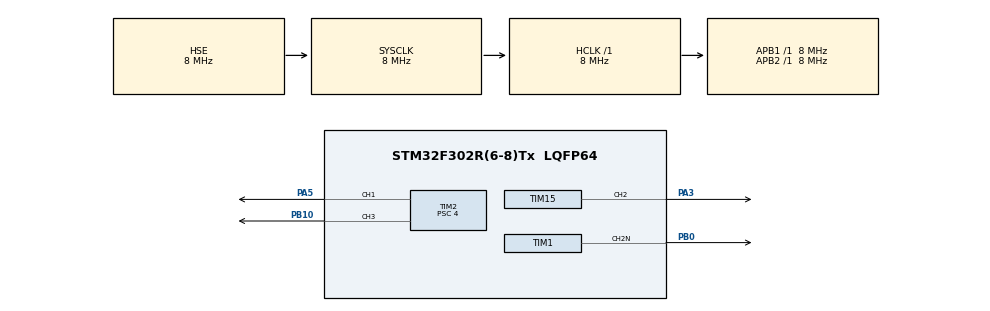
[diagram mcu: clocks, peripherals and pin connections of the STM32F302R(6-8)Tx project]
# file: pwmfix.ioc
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Mcu.Family=STM32F3
Mcu.Name=STM32F302R(6-8)Tx
Mcu.Package=LQFP64
NVIC.PriorityGroup=NVIC_PRIORITYGROUP_4
PA3.Signal=S_TIM15_CH2
PA5.Signal=S_TIM2_CH1_ETR
PB0.Mode=PWM Generation2 CH2N
PB0.Signal=TIM1_CH2N
PB10.Signal=S_TIM2_CH3
PF0-OSC_IN.Mode=HSE-External-Oscillator
PF0-OSC_IN.Signal=RCC_OSC_IN
PF1-OSC_OUT.Mode=HSE-External-Oscillator
PF1-OSC_OUT.Signal=RCC_OSC_OUT
ProjectManager.HeapSize=0x200
ProjectManager.StackSize=0x400
ProjectManager.TargetToolchain=MDK-ARM V5
RCC.AHBFreq_Value=8000000
RCC.APB1Freq_Value=8000000
RCC.APB1TimFreq_Value=8000000
RCC.APB2Freq_Value=8000000
RCC.APB2TimFreq_Value=8000000
RCC.CortexFreq_Value=8000000
RCC.HCLKFreq_Value=8000000
RCC.HSE_VALUE=8000000
RCC.HSI_VALUE=8000000
RCC.LSE_VALUE=32768
RCC.PLLSourceVirtual=RCC_PLLSOURCE_HSE
RCC.SYSCLKFreq_VALUE=8000000
RCC.SYSCLKSourceVirtual=RCC_SYSCLKSOURCE_HSE
RCC.USBFreq_Value=16000000
SH.S_TIM15_CH2.0=TIM15_CH2,PWM Generation2 CH2
SH.S_TIM2_CH1_ETR.0=TIM2_CH1,PWM Generation1 CH1
SH.S_TIM2_CH3.0=TIM2_CH3,PWM Generation3 CH3
TIM1.AutoReloadPreload=TIM_AUTORELOAD_PRELOAD_DISABLE
TIM1.Channel-PWM\ Generation2\ CH2N=TIM_CHANNEL_2
TIM1.OCNPolarity_2=TIM_OCNPOLARITY_HIGH
TIM1.Period=79
TIM1.Prescaler=4
TIM1.Pulse-PWM\ Generation2\ CH2N=39
TIM1.TIM_MasterSlaveMode=TIM_MASTERSLAVEMODE_DISABLE
TIM15.Channel-PWM\ Generation2\ CH2=TIM_CHANNEL_2
TIM15.OCPolarity_2=TIM_OCPOLARITY_LOW
TIM15.Period=79
TIM15.Prescaler=4
TIM15.Pulse-PWM\ Generation2\ CH2=39
TIM15.TIM_MasterOutputTrigger=TIM_TRGO_ENABLE
TIM15.TIM_MasterSlaveMode=TIM_MASTERSLAVEMODE_ENABLE
TIM2.AutoReloadPreload=TIM_AUTORELOAD_PRELOAD_ENABLE
TIM2.Channel-PWM\ Generation1\ CH1=TIM_CHANNEL_1
TIM2.Channel-PWM\ Generation3\ CH3=TIM_CHANNEL_3
TIM2.OCPolarity_3=TIM_OCPOLARITY_LOW
TIM2.Period=79
TIM2.Prescaler=4
TIM2.Pulse-PWM\ Generation1\ CH1=39
TIM2.Pulse-PWM\ Generation3\ CH3=39
TIM2.TIM_MasterOutputTrigger=TIM_TRGO_ENABLE
TIM2.TIM_MasterSlaveMode=TIM_MASTERSLAVEMODE_ENABLE
VP_TIM15_VS_ClockSourceINT.Mode=Internal
VP_TIM15_VS_ClockSourceITR.Mode=TriggerSource_ITR0
VP_TIM15_VS_ControllerModeTrigger.Mode=Trigger Mode
VP_TIM1_VS_ClockSourceINT.Mode=Internal
VP_TIM1_VS_ClockSourceITR.Mode=TriggerSource_ITR0
VP_TIM1_VS_ControllerModeCombinedResetTrigger.Mode=Combined_Reset_Trigger_Mode
VP_TIM2_VS_ClockSourceINT.Mode=Internal
board=custom

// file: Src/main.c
/**
  ******************************************************************************
  * @file           : main.c
  * @brief          : Main program body
  ******************************************************************************
  ** This notice applies to any and all portions of this file
  * that are not between comment pairs USER CODE BEGIN and
  * USER CODE END. Other portions of this file, whether
  * inserted by the user or by software development tools
  * are owned by their respective copyright owners.
  *
  * COPYRIGHT(c) 2019 STMicroelectronics
  *
  * Redistribution and use in source and binary forms, with or without modification,
  * are permitted provided that the following conditions are met:
  *   1. Redistributions of source code must retain the above copyright notice,
  *      this list of conditions and the following disclaimer.
  *   2. Redistributions in binary form must reproduce the above copyright notice,
  *      this list of conditions and the following disclaimer in the documentation
  *      and/or other materials provided with the distribution.
  *   3. Neither the name of STMicroelectronics nor the names of its contributors
  *      may be used to endorse or promote products derived from this software
  *      without specific prior written permission.
  *
  * THIS SOFTWARE IS PROVIDED BY THE COPYRIGHT HOLDERS AND CONTRIBUTORS "AS IS"
  * AND ANY EXPRESS OR IMPLIED WARRANTIES, INCLUDING, BUT NOT LIMITED TO, THE
  * IMPLIED WARRANTIES OF MERCHANTABILITY AND FITNESS FOR A PARTICULAR PURPOSE ARE
  * DISCLAIMED. IN NO EVENT SHALL THE COPYRIGHT HOLDER OR CONTRIBUTORS BE LIABLE
  * FOR ANY DIRECT, INDIRECT, INCIDENTAL, SPECIAL, EXEMPLARY, OR CONSEQUENTIAL
  * DAMAGES (INCLUDING, BUT NOT LIMITED TO, PROCUREMENT OF SUBSTITUTE GOODS OR
  * SERVICES; LOSS OF USE, DATA, OR PROFITS; OR BUSINESS INTERRUPTION) HOWEVER
  * CAUSED AND ON ANY THEORY OF LIABILITY, WHETHER IN CONTRACT, STRICT LIABILITY,
  * OR TORT (INCLUDING NEGLIGENCE OR OTHERWISE) ARISING IN ANY WAY OUT OF THE USE
  * OF THIS SOFTWARE, EVEN IF ADVISED OF THE POSSIBILITY OF SUCH DAMAGE.
  *
  ******************************************************************************
  */
#include "main.h"
#include "stm32f3xx_hal.h"

/* USER CODE BEGIN Includes */
#include "stdlib.h"
/* USER CODE END Includes */

TIM_HandleTypeDef htim1;
TIM_HandleTypeDef htim2;
TIM_HandleTypeDef htim15;

/* USER CODE BEGIN PV */
/* Private variables ---------------------------------------------------------*/
//TIM_HandleTypeDef htim1;
//TIM_HandleTypeDef htim2;
/* USER CODE END PV */

void SystemClock_Config(void);
static void MX_GPIO_Init(void);
static void MX_TIM1_Init(void);
static void MX_TIM2_Init(void);
static void MX_TIM15_Init(void);
void HAL_TIM_MspPostInit(TIM_HandleTypeDef *htim);

/* USER CODE BEGIN PFP */
/* Private function prototypes -----------------------------------------------*/
void updateDutyCycleBoost(int duty);
/* USER CODE END PFP */

int main(void)
{

  /* MCU Configuration----------------------------------------------------------*/

  /* Reset of all peripherals, Initializes the Flash interface and the Systick. */
  HAL_Init();

  /* Configure the system clock */
  SystemClock_Config();

  /* Initialize all configured peripherals */
  MX_GPIO_Init();
  MX_TIM1_Init();
  MX_TIM2_Init();
  MX_TIM15_Init();
  /* USER CODE BEGIN 2 */
	//HAL_TIM_PWM_Start(&htim1, TIM_CHANNEL_1);

	HAL_TIMEx_PWMN_Start(&htim1, TIM_CHANNEL_2);
	HAL_TIM_PWM_Start(&htim2, TIM_CHANNEL_1);
	HAL_TIM_PWM_Start(&htim2, TIM_CHANNEL_3);
	//HAL_TIM_PWM_Start(&htim2, TIM_CHANNEL_4);
	HAL_TIM_PWM_Start(&htim15, TIM_CHANNEL_2);

	__HAL_TIM_ENABLE(&htim2);

	updateDutyCycleBoost(50);

  /* USER CODE END 2 */

  /* Infinite loop */
  while (1)
  {

  }

}

void SystemClock_Config(void)
{

  RCC_OscInitTypeDef RCC_OscInitStruct;
  RCC_ClkInitTypeDef RCC_ClkInitStruct;
  RCC_PeriphCLKInitTypeDef PeriphClkInit;

    /**Initializes the CPU, AHB and APB busses clocks
    */
  RCC_OscInitStruct.OscillatorType = RCC_OSCILLATORTYPE_HSE;
  RCC_OscInitStruct.HSEState = RCC_HSE_ON;
  RCC_OscInitStruct.HSIState = RCC_HSI_ON;
  RCC_OscInitStruct.PLL.PLLState = RCC_PLL_NONE;
  if (HAL_RCC_OscConfig(&RCC_OscInitStruct) != HAL_OK)
  {
    _Error_Handler(__FILE__, __LINE__);
  }

    /**Initializes the CPU, AHB and APB busses clocks
    */
  RCC_ClkInitStruct.ClockType = RCC_CLOCKTYPE_HCLK|RCC_CLOCKTYPE_SYSCLK
                              |RCC_CLOCKTYPE_PCLK1|RCC_CLOCKTYPE_PCLK2;
  RCC_ClkInitStruct.SYSCLKSource = RCC_SYSCLKSOURCE_HSE;
  RCC_ClkInitStruct.AHBCLKDivider = RCC_SYSCLK_DIV1;
  RCC_ClkInitStruct.APB1CLKDivider = RCC_HCLK_DIV1;
  RCC_ClkInitStruct.APB2CLKDivider = RCC_HCLK_DIV1;

  if (HAL_RCC_ClockConfig(&RCC_ClkInitStruct, FLASH_LATENCY_0) != HAL_OK)
  {
    _Error_Handler(__FILE__, __LINE__);
  }

  PeriphClkInit.PeriphClockSelection = RCC_PERIPHCLK_TIM1|RCC_PERIPHCLK_TIM15;
  PeriphClkInit.Tim1ClockSelection = RCC_TIM1CLK_HCLK;
  PeriphClkInit.Tim15ClockSelection = RCC_TIM15CLK_HCLK;
  if (HAL_RCCEx_PeriphCLKConfig(&PeriphClkInit) != HAL_OK)
  {
    _Error_Handler(__FILE__, __LINE__);
  }

    /**Configure the Systick interrupt time
    */
  HAL_SYSTICK_Config(HAL_RCC_GetHCLKFreq()/1000);

    /**Configure the Systick
    */
  HAL_SYSTICK_CLKSourceConfig(SYSTICK_CLKSOURCE_HCLK);

  /* SysTick_IRQn interrupt configuration */
  HAL_NVIC_SetPriority(SysTick_IRQn, 0, 0);
}

/* TIM1 init function */
static void MX_TIM1_Init(void)
{

  TIM_ClockConfigTypeDef sClockSourceConfig;
  TIM_SlaveConfigTypeDef sSlaveConfig;
  TIM_MasterConfigTypeDef sMasterConfig;
  TIM_OC_InitTypeDef sConfigOC;
  TIM_BreakDeadTimeConfigTypeDef sBreakDeadTimeConfig;

  htim1.Instance = TIM1;
  htim1.Init.Prescaler = 2;
  htim1.Init.CounterMode = TIM_COUNTERMODE_UP;
  htim1.Init.Period = 132;
  htim1.Init.ClockDivision = TIM_CLOCKDIVISION_DIV1;
  htim1.Init.RepetitionCounter = 0;
  htim1.Init.AutoReloadPreload = TIM_AUTORELOAD_PRELOAD_DISABLE;
  if (HAL_TIM_Base_Init(&htim1) != HAL_OK)
  {
    _Error_Handler(__FILE__, __LINE__);
  }

  sClockSourceConfig.ClockSource = TIM_CLOCKSOURCE_INTERNAL;
  if (HAL_TIM_ConfigClockSource(&htim1, &sClockSourceConfig) != HAL_OK)
  {
    _Error_Handler(__FILE__, __LINE__);
  }

  if (HAL_TIM_PWM_Init(&htim1) != HAL_OK)
  {
    _Error_Handler(__FILE__, __LINE__);
  }

  sSlaveConfig.SlaveMode = TIM_SLAVEMODE_COMBINED_RESETTRIGGER;
  sSlaveConfig.InputTrigger = TIM_TS_ITR0;
  if (HAL_TIM_SlaveConfigSynchronization(&htim1, &sSlaveConfig) != HAL_OK)
  {
    _Error_Handler(__FILE__, __LINE__);
  }

  sMasterConfig.MasterOutputTrigger = TIM_TRGO_RESET;
  sMasterConfig.MasterOutputTrigger2 = TIM_TRGO2_RESET;
  sMasterConfig.MasterSlaveMode = TIM_MASTERSLAVEMODE_DISABLE;
  if (HAL_TIMEx_MasterConfigSynchronization(&htim1, &sMasterConfig) != HAL_OK)
  {
    _Error_Handler(__FILE__, __LINE__);
  }

  sConfigOC.OCMode = TIM_OCMODE_PWM1;
  sConfigOC.Pulse = 65;
  sConfigOC.OCPolarity = TIM_OCPOLARITY_HIGH;
  sConfigOC.OCNPolarity = TIM_OCNPOLARITY_HIGH;
  sConfigOC.OCFastMode = TIM_OCFAST_DISABLE;
  sConfigOC.OCIdleState = TIM_OCIDLESTATE_RESET;
  sConfigOC.OCNIdleState = TIM_OCNIDLESTATE_RESET;
  if (HAL_TIM_PWM_ConfigChannel(&htim1, &sConfigOC, TIM_CHANNEL_2) != HAL_OK)
  {
    _Error_Handler(__FILE__, __LINE__);
  }

  sBreakDeadTimeConfig.OffStateRunMode = TIM_OSSR_DISABLE;
  sBreakDeadTimeConfig.OffStateIDLEMode = TIM_OSSI_DISABLE;
  sBreakDeadTimeConfig.LockLevel = TIM_LOCKLEVEL_OFF;
  sBreakDeadTimeConfig.DeadTime = 0;
  sBreakDeadTimeConfig.BreakState = TIM_BREAK_DISABLE;
  sBreakDeadTimeConfig.BreakPolarity = TIM_BREAKPOLARITY_HIGH;
  sBreakDeadTimeConfig.BreakFilter = 0;
  sBreakDeadTimeConfig.Break2State = TIM_BREAK2_DISABLE;
  sBreakDeadTimeConfig.Break2Polarity = TIM_BREAK2POLARITY_HIGH;
  sBreakDeadTimeConfig.Break2Filter = 0;
  sBreakDeadTimeConfig.AutomaticOutput = TIM_AUTOMATICOUTPUT_DISABLE;
  if (HAL_TIMEx_ConfigBreakDeadTime(&htim1, &sBreakDeadTimeConfig) != HAL_OK)
  {
    _Error_Handler(__FILE__, __LINE__);
  }

  HAL_TIM_MspPostInit(&htim1);

}

/* TIM2 init function */
static void MX_TIM2_Init(void)
{

  TIM_ClockConfigTypeDef sClockSourceConfig;
  TIM_MasterConfigTypeDef sMasterConfig;
  TIM_OC_InitTypeDef sConfigOC;

  htim2.Instance = TIM2;
  htim2.Init.Prescaler = 2;
  htim2.Init.CounterMode = TIM_COUNTERMODE_UP;
  htim2.Init.Period = 132;
  htim2.Init.ClockDivision = TIM_CLOCKDIVISION_DIV1;
  htim2.Init.AutoReloadPreload = TIM_AUTORELOAD_PRELOAD_ENABLE;
  if (HAL_TIM_Base_Init(&htim2) != HAL_OK)
  {
    _Error_Handler(__FILE__, __LINE__);
  }

  sClockSourceConfig.ClockSource = TIM_CLOCKSOURCE_INTERNAL;
  if (HAL_TIM_ConfigClockSource(&htim2, &sClockSourceConfig) != HAL_OK)
  {
    _Error_Handler(__FILE__, __LINE__);
  }

  if (HAL_TIM_PWM_Init(&htim2) != HAL_OK)
  {
    _Error_Handler(__FILE__, __LINE__);
  }

  sMasterConfig.MasterOutputTrigger = TIM_TRGO_ENABLE;
  sMasterConfig.MasterSlaveMode = TIM_MASTERSLAVEMODE_ENABLE;
  if (HAL_TIMEx_MasterConfigSynchronization(&htim2, &sMasterConfig) != HAL_OK)
  {
    _Error_Handler(__FILE__, __LINE__);
  }

  sConfigOC.OCMode = TIM_OCMODE_PWM1;
  sConfigOC.Pulse = 67;
  sConfigOC.OCPolarity = TIM_OCPOLARITY_LOW;
  sConfigOC.OCFastMode = TIM_OCFAST_DISABLE;
  if (HAL_TIM_PWM_ConfigChannel(&htim2, &sConfigOC, TIM_CHANNEL_1) != HAL_OK)
  {
    _Error_Handler(__FILE__, __LINE__);
  }
	sConfigOC.Pulse = 66;
  sConfigOC.OCPolarity = TIM_OCPOLARITY_LOW;
  if (HAL_TIM_PWM_ConfigChannel(&htim2, &sConfigOC, TIM_CHANNEL_3) != HAL_OK)
  {
    _Error_Handler(__FILE__, __LINE__);
  }

  HAL_TIM_MspPostInit(&htim2);
}

/* TIM15 init function */
static void MX_TIM15_Init(void)
{

  TIM_ClockConfigTypeDef sClockSourceConfig;
  TIM_SlaveConfigTypeDef sSlaveConfig;
  TIM_MasterConfigTypeDef sMasterConfig;
  TIM_OC_InitTypeDef sConfigOC;
  TIM_BreakDeadTimeConfigTypeDef sBreakDeadTimeConfig;

  htim15.Instance = TIM15;
  htim15.Init.Prescaler = 2;
  htim15.Init.CounterMode = TIM_COUNTERMODE_UP;
  htim15.Init.Period = 132;
  htim15.Init.ClockDivision = TIM_CLOCKDIVISION_DIV1;
  htim15.Init.RepetitionCounter = 0;
  htim15.Init.AutoReloadPreload = TIM_AUTORELOAD_PRELOAD_DISABLE;
  if (HAL_TIM_Base_Init(&htim15) != HAL_OK)
  {
    _Error_Handler(__FILE__, __LINE__);
  }

  sClockSourceConfig.ClockSource = TIM_CLOCKSOURCE_INTERNAL;
  if (HAL_TIM_ConfigClockSource(&htim15, &sClockSourceConfig) != HAL_OK)
  {
    _Error_Handler(__FILE__, __LINE__);
  }

  if (HAL_TIM_PWM_Init(&htim15) != HAL_OK)
  {
    _Error_Handler(__FILE__, __LINE__);
  }

  sSlaveConfig.SlaveMode = TIM_SLAVEMODE_COMBINED_RESETTRIGGER;
  sSlaveConfig.InputTrigger = TIM_TS_ITR0;
  if (HAL_TIM_SlaveConfigSynchronization(&htim15, &sSlaveConfig) != HAL_OK)
  {
    _Error_Handler(__FILE__, __LINE__);
  }

  sMasterConfig.MasterOutputTrigger = TIM_TRGO_ENABLE;
  sMasterConfig.MasterSlaveMode = TIM_MASTERSLAVEMODE_ENABLE;
  if (HAL_TIMEx_MasterConfigSynchronization(&htim15, &sMasterConfig) != HAL_OK)
  {
    _Error_Handler(__FILE__, __LINE__);
  }

  sConfigOC.OCMode = TIM_OCMODE_PWM1;
  sConfigOC.Pulse = 66;
  sConfigOC.OCPolarity = TIM_OCPOLARITY_HIGH;
  sConfigOC.OCNPolarity = TIM_OCNPOLARITY_HIGH;
  sConfigOC.OCFastMode = TIM_OCFAST_DISABLE;
  sConfigOC.OCIdleState = TIM_OCIDLESTATE_RESET;
  sConfigOC.OCNIdleState = TIM_OCNIDLESTATE_RESET;
  if (HAL_TIM_PWM_ConfigChannel(&htim15, &sConfigOC, TIM_CHANNEL_2) != HAL_OK)
  {
    _Error_Handler(__FILE__, __LINE__);
  }

  sBreakDeadTimeConfig.OffStateRunMode = TIM_OSSR_DISABLE;
  sBreakDeadTimeConfig.OffStateIDLEMode = TIM_OSSI_DISABLE;
  sBreakDeadTimeConfig.LockLevel = TIM_LOCKLEVEL_OFF;
  sBreakDeadTimeConfig.DeadTime = 0;
  sBreakDeadTimeConfig.BreakState = TIM_BREAK_DISABLE;
  sBreakDeadTimeConfig.BreakPolarity = TIM_BREAKPOLARITY_HIGH;
  sBreakDeadTimeConfig.BreakFilter = 0;
  sBreakDeadTimeConfig.AutomaticOutput = TIM_AUTOMATICOUTPUT_DISABLE;
  if (HAL_TIMEx_ConfigBreakDeadTime(&htim15, &sBreakDeadTimeConfig) != HAL_OK)
  {
    _Error_Handler(__FILE__, __LINE__);
  }

  HAL_TIM_MspPostInit(&htim15);

}

/** Configure pins as
        * Analog
        * Input
        * Output
        * EVENT_OUT
        * EXTI
*/
static void MX_GPIO_Init(void)
{

  /* GPIO Ports Clock Enable */
  __HAL_RCC_GPIOF_CLK_ENABLE();
  __HAL_RCC_GPIOA_CLK_ENABLE();
  __HAL_RCC_GPIOB_CLK_ENABLE();

}

/* USER CODE BEGIN 4 */
void updateDutyCycleBoost(int duty){
	uint32_t pulse;
	pulse = ((htim2.Init.Period + 1) * abs(100-duty)) / 100 - 1;
	__HAL_TIM_SET_COMPARE(&htim2, TIM_CHANNEL_1, pulse+1);
	__HAL_TIM_SET_COMPARE(&htim15, TIM_CHANNEL_2, pulse);
}

/* USER CODE END 4 */

void _Error_Handler(char *file, int line)
{
  while(1)
  {
  }
}

/************************ (C) COPYRIGHT STMicroelectronics *****END OF FILE****/
